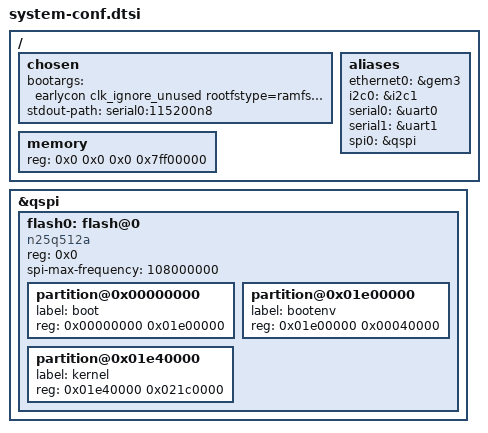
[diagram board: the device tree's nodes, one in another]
#define PLATFORM_ZCU104

/ {
	chosen {
		bootargs = "earlycon clk_ignore_unused rootfstype=ramfs earlyprintk uio_pdrv_genirq.of_id=xlnx,generic-uio cma=512M cpuidle.off=1 cpufreq.off=1";
		stdout-path = "serial0:115200n8";
	};

	aliases {
		ethernet0 = &gem3;
		i2c0 = &i2c1;
		serial0 = &uart0;
		serial1 = &uart1;
		spi0 = &qspi;
	};

	memory {
		device_type = "memory";
		reg = <0x0 0x0 0x0 0x7ff00000>;
	};
};

&qspi {
	#address-cells = <1>;
	#size-cells = <0>;
	flash0: flash@0 {
		compatible = "n25q512a","micron,m25p80";
		reg = <0x0>;
		#address-cells = <1>;
		#size-cells = <1>;
		spi-max-frequency = <108000000>;
		/delete-node/ partition@qspi-fsbl-uboot;
		/delete-node/ partition@qspi-linux;
		/delete-node/ partition@qspi-device-tree;
		/delete-node/ partition@qspi-rootfs;
		/delete-node/ partition@qspi-bitstream;
		partition@0x00000000 {
			label = "boot";
			reg = <0x00000000 0x01e00000>;
		};
		partition@0x01e00000 {
			label = "bootenv";
			reg = <0x01e00000 0x00040000>;
		};
		partition@0x01e40000 {
			label = "kernel";
			reg = <0x01e40000 0x021c0000>;
		};
	};
};

